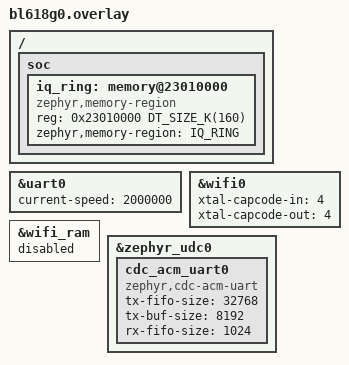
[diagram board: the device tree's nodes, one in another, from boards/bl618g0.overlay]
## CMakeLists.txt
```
# SPDX-FileCopyrightText: Copyright The Zephyr Project Contributors
# SPDX-License-Identifier: Apache-2.0

cmake_minimum_required(VERSION 3.28.0)
find_package(Zephyr REQUIRED HINTS $ENV{ZEPHYR_BASE})
project(bl61x_sdr)

target_sources(app PRIVATE
  src/capture.c
  src/dump_ring.c
  src/iq_control.c
  src/iq_format.c
  src/iq_usb.c
  src/main.c
  src/resample.c
  src/rf.c
  src/stream_ring.c
)
```

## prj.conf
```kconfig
# SPDX-FileCopyrightText: Copyright The Zephyr Project Contributors
# SPDX-License-Identifier: Apache-2.0

CONFIG_BFLB_BL61X_SDR=y
CONFIG_CRC=y
CONFIG_SERIAL=y
CONFIG_UART_INTERRUPT_DRIVEN=y
CONFIG_LOG=n
CONFIG_BOOT_BANNER=n

# USB: vendor stream interface plus CDC-ACM (burst protocol for Web Serial).
# Seven endpoints need the four data FIFOs shared by both directions.
CONFIG_USB_DEVICE_STACK_NEXT=y
CONFIG_UDC_BFLB_V2_FIFO_BIDIR=y
CONFIG_USBD_CDC_ACM_CLASS=y
CONFIG_USBD_CDC_ACM_WORKQUEUE=y
CONFIG_JSON_LIBRARY=y

# UART protocol below the USB stream and producer threads
CONFIG_MAIN_THREAD_PRIORITY=5
CONFIG_MAIN_STACK_SIZE=2048
```

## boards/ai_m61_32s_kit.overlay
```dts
/*
 * SPDX-FileCopyrightText: Copyright The Zephyr Project Contributors
 *
 * SPDX-License-Identifier: Apache-2.0
 */

/* The ESP-SDR web viewer opens the port at 2 MBaud */
&uart0 {
	current-speed = <2000000>;
};

/*
 * RF dump window: all 160 KiB of WRAM, the continuous ring uses the first
 * 128 KiB. The dump engine addresses it as its WRAM bank (0x21010000); the
 * CPU reaches it through the bus remap views at 0x23010000 (non-cached) and
 * 0x63010000 (cached); the 0x21xxxxxx view is not CPU accessible. The
 * wifi_ram region covers the same memory.
 */
&wifi_ram {
	status = "disabled";
};

/ {
	soc {
		iq_ring: memory@23010000 {
			compatible = "zephyr,memory-region", "mmio-sram";
			reg = <0x23010000 DT_SIZE_K(160)>;
			zephyr,memory-region = "IQ_RING";
		};
	};
};

/* Burst protocol over USB CDC-ACM (Web Serial), next to the vendor stream */
&zephyr_udc0 {
	cdc_acm_uart0: cdc_acm_uart0 {
		compatible = "zephyr,cdc-acm-uart";
		tx-fifo-size = <32768>;
		tx-buf-size = <8192>;
		rx-fifo-size = <1024>;
	};
};
```

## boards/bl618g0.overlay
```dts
/*
 * SPDX-FileCopyrightText: Copyright The Zephyr Project Contributors
 *
 * SPDX-License-Identifier: Apache-2.0
 */

/* The ESP-SDR web viewer opens the port at 2 MBaud */
&uart0 {
	current-speed = <2000000>;
};

/*
 * Crystal load trim, measured on a BL618G0 board against a CW reference (the
 * eFuse capcode slots are empty): the default 36 receives 39 ppm high, 4
 * within 1 ppm. Other boards may need a few steps more or less (1.4 ppm/step).
 */
&wifi0 {
	xtal-capcode-in = <4>;
	xtal-capcode-out = <4>;
};

/*
 * RF dump window: all 160 KiB of WRAM, the continuous ring uses the first
 * 128 KiB. The dump engine addresses it as its WRAM bank (0x21010000); the
 * CPU reaches it through the bus remap views at 0x23010000 (non-cached) and
 * 0x63010000 (cached); the 0x21xxxxxx view is not CPU accessible. The
 * wifi_ram region covers the same memory.
 */
&wifi_ram {
	status = "disabled";
};

/ {
	soc {
		iq_ring: memory@23010000 {
			compatible = "zephyr,memory-region", "mmio-sram";
			reg = <0x23010000 DT_SIZE_K(160)>;
			zephyr,memory-region = "IQ_RING";
		};
	};
};

/* Burst protocol over USB CDC-ACM (Web Serial), next to the vendor stream */
&zephyr_udc0 {
	cdc_acm_uart0: cdc_acm_uart0 {
		compatible = "zephyr,cdc-acm-uart";
		tx-fifo-size = <32768>;
		tx-buf-size = <8192>;
		rx-fifo-size = <1024>;
	};
};
```

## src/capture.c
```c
/*
 * SPDX-FileCopyrightText: Copyright The Zephyr Project Contributors
 *
 * SPDX-License-Identifier: Apache-2.0
 */

#include <string.h>

#include <zephyr/kernel.h>
#include <zephyr/spinlock.h>

#include "capture.h"
#include "dump_ring.h"
#include "iq_usb.h"
#include "rf.h"
#include "stream_ring.h"

#define HZ_PER_MHZ                1000000U
#define RF_FREQ_DEFAULT_HZ        (RF_FREQ_DEFAULT_MHZ * HZ_PER_MHZ)
#define RF_FREQ_MIN_HZ            (RF_FREQ_MIN_MHZ * HZ_PER_MHZ)
#define RF_FREQ_MAX_HZ            (RF_FREQ_MAX_MHZ * HZ_PER_MHZ)
#define TX_GAIN_DEFAULT           8U
#define BW_DEFAULT_MHZ            20U
#define LOOPBACK_TX_GAIN_DEFAULT  124U
#define LOOPBACK_RX_GAIN_DEFAULT  0x73U
#define LOOPBACK_BB_GAIN_DEFAULT  0x3fU
#define TX_TONE0_STEP_DEFAULT     16
#define TRIGGER_INTERVAL_DEFAULT  2501U
#define TRIGGER_DURATION_DEFAULT  1U
#define RX_FILTER_BW_OPEN         0U
#define RX_FILTER_BW_MIN_MHZ      13U
#define RX_FILTER_BW_MAX_MHZ      54U
#define RX_FILTER_MODE_DEFAULT    16U
#define RX_FILTER_MODE_MAX        32U
#define RX_FILTER_DCAP_MAX        63U
#define RX_FILTER_NARROW_DCAP     60U
#define WIFI_DUMMY_TX_INTERVAL_MS 1000U
#define IQ_AGC_TRIGGER_STATE_MASK_ALL 0xffffU
#define IQ_AGC_TRIGGER_MATCH_FSM      0U
#define IQ_AGC_TRIGGER_MATCH_MAX_GAIN 1U
#define TRIGGER_CFG_INTERVAL      0U
#define TRIGGER_CFG_OFFSET        1U
#define TRIGGER_CFG_DURATION      2U
#define TRIGGER_CFG_CHECKS        0U
#define TRIGGER_CFG_PRE           1U
#define TRIGGER_CFG_POST          2U
#define TRIGGER_CFG_LEVEL         3U
#define TRIGGER_CFG_STATE_MASK    4U
#define TRIGGER_CFG_DC_SHIFT      4U
#define TRIGGER_CFG_MATCH         5U
#define STALE_APPLY_US            500000U
#define PIPELINE_IDLE_TRIES       100U
#define PIPELINE_IDLE_SLEEP_MS    1
#define ARM_DELAY_MS              100

enum {
	CONFIG_STAGE_APPLY_START = 1U,
	CONFIG_STAGE_AFTER_WIFI = 2U,
	CONFIG_STAGE_BEFORE_MODEM_APPLY = 3U,
	CONFIG_STAGE_AFTER_MODEM_APPLY = 4U,
	CONFIG_STAGE_BEFORE_RESTART = 6U,
	CONFIG_STAGE_AFTER_RESTART = 7U,
	CONFIG_STAGE_RESTART_ENTRY = 20U,
	CONFIG_STAGE_AFTER_ENGINE_ENABLE = 21U,
	CONFIG_STAGE_AFTER_STREAM_STATE = 25U,
};

static struct capture_config config = {
	.radio = {.rf_freq_hz = RF_FREQ_DEFAULT_HZ},
	.gain = {.gain_mode = GAIN_MODE_MANUAL,
		 .rx_gain = RF_GAIN_DEFAULT,
		 .tx_gain = TX_GAIN_DEFAULT},
	.bandwidth = {.bw_mhz = BW_DEFAULT_MHZ, .second_chan = SECOND_CHAN_NONE},
	.loopback = {.loopback_tx_gain = LOOPBACK_TX_GAIN_DEFAULT,
		     .loopback_rx_gain = LOOPBACK_RX_GAIN_DEFAULT,
		     .loopback_bb_gain = LOOPBACK_BB_GAIN_DEFAULT},
	.tx = {.tx_tone0_step = TX_TONE0_STEP_DEFAULT},
	.iq_engine = {.adc_decimation = 1U, .adc_source_sel = 0U},
	.trigger = {.trigger_mode = IQ_TRIGGER_MODE_INTERVAL,
		    .trigger_config = {TRIGGER_INTERVAL_DEFAULT, 0U, TRIGGER_DURATION_DEFAULT}},
	.rx_filter = {.filter_bw_mhz = RX_FILTER_BW_OPEN,
		      .rx_filter_mode = RX_FILTER_MODE_DEFAULT,
		      .rx_filter_dcap = RX_FILTER_NARROW_DCAP},
	.wifi_tx = {.wifi_dummy_tx_interval_ms = WIFI_DUMMY_TX_INTERVAL_MS},
	.dc_offset = {.automatic = 0U},
};
static struct trigger_plan plan;
static struct capture_config pending_config;
static struct trigger_plan pending_plan;
static bool apply_pending;
static bool apply_in_progress;
static uint64_t apply_started_us;
static atomic_t capture_armed;
/* A UART snapshot owns the dump window and the RF tuning */
static bool uart_owner;
static struct k_spinlock lock;

static void arm_work_handler(struct k_work *work);
static K_WORK_DELAYABLE_DEFINE(arm_work, arm_work_handler);

static uint64_t now_us(void);
static struct capture_config sanitize(struct capture_config c);
static struct trigger_plan build_trigger_plan(const struct capture_config *c);
static bool consume_pending(void);
static void finish_apply(void);
static void recover_stale_apply(void);
static void push_stage_report(const struct capture_config *c, uint32_t stage);
static void wait_pipeline_idle(void);
static void engine_disable(void);
static void restart_capture(const struct capture_config *c);
static void apply_pending_config(void);

static uint64_t now_us(void)
{
	return k_cyc_to_us_floor64(k_cycle_get_64());
}

static void arm_work_handler(struct k_work *work)
{
	ARG_UNUSED(work);
	iq_usb_stream_armed_set(true);
}

static struct capture_config sanitize(struct capture_config c)
{
	c.radio.rf_freq_hz = CLAMP(c.radio.rf_freq_hz, RF_FREQ_MIN_HZ, RF_FREQ_MAX_HZ);
	/* rfc_config_channel() resolution is 1 MHz */
	c.radio.rf_freq_hz = ((c.radio.rf_freq_hz + (HZ_PER_MHZ / 2U)) / HZ_PER_MHZ) * HZ_PER_MHZ;
	c.bandwidth.bw_mhz = BW_DEFAULT_MHZ;
	c.bandwidth.second_chan = SECOND_CHAN_NONE;
	c.gain.tx_gain = MIN(c.gain.tx_gain, TX_GAIN_MAX);
	c.dc_offset.automatic = (c.dc_offset.automatic != 0U) ? 1U : 0U;
	if ((c.rx_filter.rx_filter_override == 0U) &&
	    (c.rx_filter.filter_bw_mhz != RX_FILTER_BW_OPEN)) {
		c.rx_filter.filter_bw_mhz = CLAMP(c.rx_filter.filter_bw_mhz, RX_FILTER_BW_MIN_MHZ,
						  RX_FILTER_BW_MAX_MHZ);
	}
	c.rx_filter.rx_filter_dcap = MIN(c.rx_filter.rx_filter_dcap, RX_FILTER_DCAP_MAX);
	c.rx_filter.rx_filter_mode = MIN(c.rx_filter.rx_filter_mode, RX_FILTER_MODE_MAX);

	return c;
}

static struct trigger_plan build_trigger_plan(const struct capture_config *c)
{
	struct trigger_plan p = {
		.mode = c->trigger.trigger_mode,
		.interval_chunks = c->trigger.trigger_config[TRIGGER_CFG_INTERVAL],
		.interval_duration_chunks = c->trigger.trigger_config[TRIGGER_CFG_DURATION],
		.checks_per_chunk = 1U,
	};
	uint32_t sample_stride;

	if (p.interval_chunks == 0U) {
		p.interval_chunks = 1U;
	}
	p.interval_offset_chunks =
		c->trigger.trigger_config[TRIGGER_CFG_OFFSET] % p.interval_chunks;

	if (c->trigger.trigger_mode == IQ_TRIGGER_MODE_AGC) {
		uint32_t match_mode = c->trigger.trigger_config[TRIGGER_CFG_MATCH];

		p.checks_per_chunk = c->trigger.trigger_config[TRIGGER_CFG_CHECKS];
		p.pre_chunks = c->trigger.trigger_config[TRIGGER_CFG_PRE];
		p.post_chunks = c->trigger.trigger_config[TRIGGER_CFG_POST];
		p.max_gain = c->trigger.trigger_config[TRIGGER_CFG_LEVEL];
		p.state_mask = c->trigger.trigger_config[TRIGGER_CFG_STATE_MASK] &
			       IQ_AGC_TRIGGER_STATE_MASK_ALL;
		p.use_fsm_match = match_mode != IQ_AGC_TRIGGER_MATCH_MAX_GAIN;
		p.use_max_gain_match = match_mode != IQ_AGC_TRIGGER_MATCH_FSM;
	} else if (c->trigger.trigger_mode == IQ_TRIGGER_MODE_POWER) {
		p.checks_per_chunk = c->trigger.trigger_config[TRIGGER_CFG_CHECKS];
		p.pre_chunks = c->trigger.trigger_config[TRIGGER_CFG_PRE];
		p.post_chunks = c->trigger.trigger_config[TRIGGER_CFG_POST];
		p.threshold = c->trigger.trigger_config[TRIGGER_CFG_LEVEL];
		p.dc_shift = c->trigger.trigger_config[TRIGGER_CFG_DC_SHIFT];
	} else {
		/* interval mode uses only the interval fields */
	}
	p.checks_per_chunk = CLAMP(p.checks_per_chunk, 1U, IQ_AGC_TRIGGER_MAX_CHECKS_PER_CHUNK);
	sample_stride = MAX(IQ_CHUNK_SAMPLE_WORDS / p.checks_per_chunk, 1U);
	for (uint32_t check = 0U; check < p.checks_per_chunk; check++) {
		p.sample_offsets[check] = (uint16_t)(check * sample_stride);
	}

	return p;
}

static bool consume_pending(void)
{
	k_spinlock_key_t key = k_spin_lock(&lock);
	bool pending = apply_pending && !apply_in_progress;

	if (pending) {
		config = pending_config;
		plan = pending_plan;
		apply_pending = false;
		apply_in_progress = true;
		apply_started_us = now_us();
	}
	k_spin_unlock(&lock, key);

	return pending;
}

static void finish_apply(void)
{
	k_spinlock_key_t key = k_spin_lock(&lock);

	apply_in_progress = false;
	apply_started_us = 0U;
	k_spin_unlock(&lock, key);
}

static void recover_stale_apply(void)
{
	k_spinlock_key_t key = k_spin_lock(&lock);

	if (apply_in_progress && (apply_started_us != 0U) &&
	    ((now_us() - apply_started_us) > STALE_APPLY_US)) {
		apply_in_progress = false;
		apply_started_us = 0U;
	}
	k_spin_unlock(&lock, key);
}

static void push_stage_report(const struct capture_config *c, uint32_t stage)
{
	struct config_report report = {
		.magic = {'C', 'F', 'G', '1'},
		.uptime_ms = k_uptime_get_32(),
		.stage = stage,
		.rx_gain = c->gain.rx_gain,
		.loopback = c->loopback.loopback,
		.tx_tone_enable = c->tx.tx_tone_enable,
		.adc_source_sel = c->iq_engine.adc_source_sel,
		.expert_gain_word0 = c->gain.expert_gain_word0,
		.expert_gain_word1 = c->gain.expert_gain_word1,
		.ctrl = rf_dump_ctrl_read(),
		.mode = rf_dump_cfg_read(),
		.hp_tcm_dump_ctrl = 0U,
		.trigger_interval_chunks = c->trigger.trigger_config[TRIGGER_CFG_INTERVAL],
		.trigger_duration_chunks = c->trigger.trigger_config[TRIGGER_CFG_DURATION],
	};

	(void)stream_ring_push_config_report(&report);
}

static void wait_pipeline_idle(void)
{
	for (uint32_t i = 0U; (i < PIPELINE_IDLE_TRIES) &&
			      (iq_usb_stream_write_active() || dump_ring_producer_active());
	     i++) {
		k_msleep(PIPELINE_IDLE_SLEEP_MS);
	}
}

static void engine_disable(void)
{
	rf_ring_stop();
}

static void restart_capture(const struct capture_config *c)
{
	push_stage_report(c, CONFIG_STAGE_RESTART_ENTRY);
	dump_ring_restart_tracking();
	capture_engine_enable();
	push_stage_report(c, CONFIG_STAGE_AFTER_ENGINE_ENABLE);
	wait_pipeline_idle();
	dump_ring_stream_state_reset();
	push_stage_report(c, CONFIG_STAGE_AFTER_STREAM_STATE);
}

static void apply_pending_config(void)
{
	static struct capture_config applied;
	static bool have_applied;
	struct capture_config c;
	struct trigger_plan p;

	capture_snapshot(&c, &p);
	if (have_applied && (memcmp(&applied, &c, sizeof(c)) == 0) && capture_engine_running()) {
		return;
	}

	push_stage_report(&c, CONFIG_STAGE_APPLY_START);
	wait_pipeline_idle();
	/* Retuning touches the RF block the dump engine reads from */
	engine_disable();
	push_stage_report(&c, CONFIG_STAGE_AFTER_WIFI);
	push_stage_report(&c, CONFIG_STAGE_BEFORE_MODEM_APPLY);
	if (c.gain.gain_mode != GAIN_MODE_AUTO) {
		rf_gain_set(c.gain.rx_gain);
	}
	rf_tune(c.radio.rf_freq_hz / HZ_PER_MHZ);
	rf_dump_sel_set(c.iq_engine.adc_source_sel);
	push_stage_report(&c, CONFIG_STAGE_AFTER_MODEM_APPLY);
	push_stage_report(&c, CONFIG_STAGE_BEFORE_RESTART);
	restart_capture(&c);
	push_stage_report(&c, CONFIG_STAGE_AFTER_RESTART);
	applied = c;
	have_applied = true;
}

void capture_get_config(struct capture_config *out)
{
	k_spinlock_key_t key = k_spin_lock(&lock);

	*out = config;
	k_spin_unlock(&lock, key);
}

void capture_snapshot(struct capture_config *out_config, struct trigger_plan *out_plan)
{
	k_spinlock_key_t key = k_spin_lock(&lock);

	*out_config = config;
	*out_plan = plan;
	k_spin_unlock(&lock, key);
}

const char *capture_validate_config(const struct capture_config *c)
{
	if (c->gain.gain_mode > GAIN_MODE_EXPERT) {
		return "gain_mode must be 0 (auto), 1 (manual), or 2 (expert)";
	}
	if ((c->gain.gain_mode == GAIN_MODE_MANUAL) && (c->gain.rx_gain >= GAIN_TABLE_ENTRIES)) {
		return "manual rx_gain exceeds the calibrated gain table";
	}
	if (c->gain.tx_gain > TX_GAIN_MAX) {
		return "tx_gain must be in the range 0..63";
	}
	if ((c->radio.frequency_correction_ppb < -RF_CORRECTION_MAX_PPB) ||
	    (c->radio.frequency_correction_ppb > RF_CORRECTION_MAX_PPB)) {
		return "frequency_correction_ppb must be in the range -100000..100000";
	}
	if (c->dc_offset.automatic > 1U) {
		return "dc_offset automatic must be 0 or 1";
	}
	/* BL61x dump words carry no AGC state */
	if (c->trigger.trigger_mode == IQ_TRIGGER_MODE_AGC) {
		return "AGC trigger is not supported on BL61x";
	}
	if (c->trigger.trigger_mode > IQ_TRIGGER_MODE_POWER) {
		return "trigger_mode must be 0 (interval), 1 (agc), or 2 (power)";
	}

	return NULL;
}

void capture_apply_config(const struct capture_config *c)
{
	struct capture_config sanitized = sanitize(*c);
	struct trigger_plan p = build_trigger_plan(&sanitized);
	k_spinlock_key_t key = k_spin_lock(&lock);

	pending_config = sanitized;
	pending_plan = p;
	apply_pending = true;
	k_spin_unlock(&lock, key);
}

void capture_service_pending_config(void)
{
	k_spinlock_key_t key = k_spin_lock(&lock);
	bool uart_busy = uart_owner;

	k_spin_unlock(&lock, key);
	/* Deferred until the UART snapshot releases the dump window */
	if (uart_busy) {
		return;
	}

	recover_stale_apply();
	if (consume_pending()) {
		apply_pending_config();
		finish_apply();
	}
	if ((atomic_get(&capture_armed) == 0) && capture_engine_running()) {
		wait_pipeline_idle();
		engine_disable();
		dump_ring_stream_state_reset();
	}
}

bool capture_config_applying(void)
{
	k_spinlock_key_t key = k_spin_lock(&lock);
	bool applying = apply_pending || apply_in_progress;

	k_spin_unlock(&lock, key);

	return applying;
}

/*
 * Stream ownership: a fresh engine start is serialized in the stream thread
 * and the stream is armed only after it and its reports have completed.
 */
void capture_set_armed(bool armed)
{
	k_spinlock_key_t key = k_spin_lock(&lock);

	atomic_set(&capture_armed, armed ? 1 : 0);
	k_spin_unlock(&lock, key);
	if (armed) {
		struct capture_config c;

		/* Keep a configuration the host queued just before arming */
		key = k_spin_lock(&lock);
		c = apply_pending ? pending_config : config;
		k_spin_unlock(&lock, key);
		capture_apply_config(&c);
		(void)k_work_reschedule(&arm_work, K_MSEC(ARM_DELAY_MS));
	} else {
		(void)k_work_cancel_delayable(&arm_work);
		iq_usb_stream_armed_set(false);
	}
}

bool capture_uart_claim(void)
{
	k_spinlock_key_t key = k_spin_lock(&lock);
	bool claimed = (atomic_get(&capture_armed) == 0) && !uart_owner &&
		       !apply_pending && !apply_in_progress && !capture_engine_running();

	if (claimed) {
		uart_owner = true;
	}
	k_spin_unlock(&lock, key);

	return claimed;
}

void capture_uart_release(void)
{
	k_spinlock_key_t key = k_spin_lock(&lock);

	uart_owner = false;
	k_spin_unlock(&lock, key);
}

bool capture_engine_running(void)
{
	return rf_ring_running();
}

void capture_engine_enable(void)
{
	rf_ring_start();
}

uint32_t capture_decimation(const struct capture_config *c)
{
	return CLAMP(c->iq_engine.adc_decimation, 1U, ADC_DECIMATION_MAX);
}

uint32_t capture_sample_rate_hz(const struct capture_config *c)
{
	return RF_SAMPLE_RATE_HZ / capture_decimation(c);
}
```

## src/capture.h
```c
/*
 * SPDX-FileCopyrightText: Copyright The Zephyr Project Contributors
 *
 * SPDX-License-Identifier: Apache-2.0
 */

/*
 * Capture configuration and engine control, mirroring the ESP-SDR streaming
 * firmware: the host configuration document, the trigger plan and the
 * serialized configuration apply sequence.
 */

#ifndef BL61X_SDR_CAPTURE_H_
#define BL61X_SDR_CAPTURE_H_

#include <stdbool.h>
#include <stdint.h>

#include <zephyr/toolchain.h>

#include "rf.h"

#define IQ_TRIGGER_CONFIG_WORDS             16U
#define IQ_AGC_TRIGGER_MAX_CHECKS_PER_CHUNK 32U
#define ADC_DECIMATION_MAX                  10U
#define TX_GAIN_MAX                         63U
#define RF_CORRECTION_MAX_PPB               100000
/* Entries of the RX gain ladder (rf.h) */
#define GAIN_TABLE_ENTRIES                  RF_GAIN_STEPS

enum {
	GAIN_MODE_AUTO = 0U,
	GAIN_MODE_MANUAL = 1U,
	GAIN_MODE_EXPERT = 2U,
};

enum {
	IQ_TRIGGER_MODE_INTERVAL = 0U,
	IQ_TRIGGER_MODE_AGC = 1U,
	IQ_TRIGGER_MODE_POWER = 2U,
};

enum {
	SECOND_CHAN_NONE = 0U,
	SECOND_CHAN_ABOVE = 1U,
	SECOND_CHAN_BELOW = 2U,
};

struct capture_config {
	struct {
		uint32_t stream_wifi_packets;
	} stream;
	struct {
		uint32_t rf_freq_hz;
		int32_t frequency_correction_ppb;
	} radio;
	struct {
		uint32_t gain_mode;
		uint32_t rx_gain;
		uint32_t tx_gain;
		uint32_t expert_gain_word0;
		uint32_t expert_gain_word1;
		uint32_t expert_gain_word2;
	} gain;
	struct {
		uint32_t bw_mhz;
		uint32_t second_chan;
	} bandwidth;
	struct {
		uint32_t loopback;
		uint32_t loopback_tx_gain;
		uint32_t loopback_rx_gain;
		uint32_t loopback_bb_gain;
	} loopback;
	struct {
		uint32_t tx_tone_enable;
		int32_t tx_tone0_step;
	} tx;
	struct {
		uint32_t adc_decimation;
		uint32_t adc_source_sel;
	} iq_engine;
	struct {
		uint32_t trigger_mode;
		uint32_t trigger_config[IQ_TRIGGER_CONFIG_WORDS];
	} trigger;
	struct {
		uint32_t filter_bw_mhz;
		uint32_t rx_filter_override;
		uint32_t rx_filter_mode;
		uint32_t rx_filter_dcap;
	} rx_filter;
	struct {
		uint32_t wifi_dummy_tx_enable;
		uint32_t wifi_dummy_tx_interval_ms;
	} wifi_tx;
	struct {
		uint32_t automatic;
	} dc_offset;
};

BUILD_ASSERT(sizeof(struct capture_config) == 172U, "host CaptureConfig must match firmware");

struct trigger_plan {
	uint32_t mode;
	uint32_t interval_chunks;
	uint32_t interval_offset_chunks;
	uint32_t interval_duration_chunks;
	uint32_t checks_per_chunk;
	uint32_t pre_chunks;
	uint32_t post_chunks;
	uint32_t max_gain;
	uint32_t state_mask;
	uint32_t threshold;
	uint32_t dc_shift;
	bool use_fsm_match;
	bool use_max_gain_match;
	uint16_t sample_offsets[IQ_AGC_TRIGGER_MAX_CHECKS_PER_CHUNK];
};

void capture_get_config(struct capture_config *config);
void capture_snapshot(struct capture_config *config, struct trigger_plan *plan);
/* Validates a host configuration; returns NULL or an error message */
const char *capture_validate_config(const struct capture_config *config);
/* Queues a configuration for the serialized apply in the stream thread */
void capture_apply_config(const struct capture_config *config);
void capture_service_pending_config(void);
bool capture_config_applying(void);
void capture_set_armed(bool armed);
/*
 * Claims the dump window and the RF tuning for a UART command. Fails while a
 * USB host owns the stream or a configuration apply is pending.
 */
bool capture_uart_claim(void);
void capture_uart_release(void);
bool capture_engine_running(void);
void capture_engine_enable(void);
uint32_t capture_decimation(const struct capture_config *config);
uint32_t capture_sample_rate_hz(const struct capture_config *config);

#endif /* BL61X_SDR_CAPTURE_H_ */
```

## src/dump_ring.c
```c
/*
 * SPDX-FileCopyrightText: Copyright The Zephyr Project Contributors
 *
 * SPDX-License-Identifier: Apache-2.0
 */

/*
 * Dump ring consumer, ported from the ESP-SDR streaming firmware.
 *
 * The dump engine writes continuously into a ring of RF_RING_WORDS words.
 * The producer turns the hardware write position into an absolute 64-bit
 * write count, emits fixed chunks that are at least a guard distance behind
 * the writer, skips half a ring and counts drops when it falls too far
 * behind, and queues the chunks as stream frames.
 *
 * Single core adaptation: waits longer than two kernel ticks sleep instead of
 * spinning (ending two ticks early, since a sleep may overshoot), and the
 * producer blocks on the frame queue when it is full, so the transport
 * thread keeps running.
 */

#include <zephyr/kernel.h>
#include <zephyr/sys/util.h>

#include "capture.h"
#include "dump_ring.h"
#include "iq_format.h"
#include "iq_usb.h"
#include "rf.h"
#include "stream_ring.h"

#define RING_GUARD_WORDS          (12U * IQ_CHUNK_SAMPLE_WORDS)
#define LIVE_COPY_GUARD_WORDS     256U
#define RING_MAX_CHUNKS_PER_POLL  16U
#define POLL_CLOSE_US             20U
#define POLL_WAKE_MARGIN_US       30000U
#define POLL_WAKE_SLACK_US        1000U
#define US_PER_MS                 1000U
#define US_PER_S                  1000000ULL
#define TICK_US                   (USEC_PER_SEC / CONFIG_SYS_CLOCK_TICKS_PER_SEC)
/* k_usleep() may overshoot by up to two ticks */
#define SLEEP_SLACK_US            (2U * TICK_US)
#define IDLE_DELAY_MS             2
#define APPLY_DELAY_MS            1
#define SLOT_WAIT_MS              1U
#define DC_Q16_SHIFT              16U
#define DC_Q16_SCALE              65536
#define CHUNKS_PER_WINDOW         (RF_RING_WORDS / IQ_CHUNK_SAMPLE_WORDS)
/* Software AGC in auto gain mode: one chunk measured every interval */
#define AGC_INTERVAL_US           2000U

#define PRODUCER_STACK_SIZE       2048
#define PRODUCER_PRIORITY         3

BUILD_ASSERT((RF_RING_WORDS % IQ_CHUNK_SAMPLE_WORDS) == 0U, "dump ring must be chunk-aligned");

enum {
	CHUNK_STREAM_SKIP = 0U,
	CHUNK_STREAM_TRIGGER = 1U,
	CHUNK_STREAM_PRE = 2U,
	CHUNK_STREAM_POST = 3U,
};

static uint32_t emit_chunk;
static bool ring_started;
static uint32_t source_chunk_index;
static uint32_t dropped_chunks;
static uint64_t abs_write_accum;
static uint32_t prev_sa;
static uint64_t abs_track_us;
static uint32_t dbg_lo;
static uint64_t diag_abs_write;
static uint32_t copy_source_chunk;
static bool power_dc_valid;
static int32_t power_dc_i_q16;
static int32_t power_dc_q_q16;
static volatile bool producer_active;
static uint8_t chunk_mark[RING_MAX_CHUNKS_PER_POLL];
static uint32_t decim_buf[IQ_CHUNK_SAMPLE_WORDS];
static uint64_t agc_last_us;
static uint32_t agc_gain_changes;

static void producer_thread(void *p1, void *p2, void *p3);
K_THREAD_DEFINE(producer_tid, PRODUCER_STACK_SIZE, producer_thread, NULL, NULL, NULL,
		PRODUCER_PRIORITY, 0, SYS_FOREVER_MS);

static uint64_t now_us(void);
static uint32_t ring_mod(uint32_t value);
static uint32_t ring_delta(uint32_t cur, uint32_t prev);
static uint32_t abs_u32(int32_t value);
static uint32_t output_chunk_words(const struct capture_config *config);
static uint32_t ring_guard_words(const struct trigger_plan *plan);
static uint32_t interval_next_selected(const struct trigger_plan *plan, uint32_t chunk);
static uint32_t interval_selected_count(const struct trigger_plan *plan, uint32_t first_chunk,
					uint32_t end_chunk);
static bool interval_prev_selected(const struct trigger_plan *plan, uint32_t end_chunk,
				   uint32_t *selected_chunk);
static bool chunk_triggers(const struct trigger_plan *plan, const uint32_t *words, int32_t *sum_i,
			   int32_t *sum_q, uint32_t *sum_n, int32_t dc_i, int32_t dc_q,
			   bool dc_valid);
static void expand_pre_post(uint8_t *mask, uint32_t n, uint32_t pre, uint32_t post);
static uint64_t current_abs_write(void);
static const uint32_t *chunk_words(const struct capture_config *config, uint32_t start_word);
static const uint32_t *chunk_source(const struct capture_config *config, uint32_t c,
				    uint64_t abs_write);
static const uint32_t *exact_chunk_source(const struct capture_config *config,
					  uint32_t source_chunk);
static void fill_and_push_chunk(const struct capture_config *config, const uint32_t *words,
				uint32_t source_chunk, uint32_t sample_rate_hz, uint32_t rx_gain,
				uint32_t agc_state, union stream_frame *slot);
static void process_interval_exact(const struct capture_config *config,
				   const struct trigger_plan *plan, uint64_t abs_write,
				   uint32_t c_hi, uint32_t sample_rate_hz, uint32_t rx_gain);
static void process_interval_latest(const struct capture_config *config,
				    const struct trigger_plan *plan, uint64_t abs_write,
				    uint32_t c_hi, uint32_t sample_rate_hz, uint32_t rx_gain);
static void process_triggered(const struct capture_config *config,
			      const struct trigger_plan *plan, uint64_t abs_write, uint32_t c_hi,
			      uint32_t sample_rate_hz, uint32_t rx_gain);
static void process_dump_ring(const struct capture_config *config,
			      const struct trigger_plan *plan);
static void agc_service(const struct capture_config *config);
static void wait_until_next_ring_window(const struct capture_config *config,
					const struct trigger_plan *plan);

static uint64_t now_us(void)
{
	return k_cyc_to_us_floor64(k_cycle_get_64());
}

static uint32_t ring_mod(uint32_t value)
{
	return value % RF_RING_WORDS;
}

static uint32_t ring_delta(uint32_t cur, uint32_t prev)
{
	return (cur + RF_RING_WORDS - prev) % RF_RING_WORDS;
}

static uint32_t abs_u32(int32_t value)
{
	return (value < 0) ? (0U - (uint32_t)value) : (uint32_t)value;
}

static uint32_t output_chunk_words(const struct capture_config *config)
{
	return IQ_CHUNK_SAMPLE_WORDS * capture_decimation(config);
}

static uint32_t ring_guard_words(const struct trigger_plan *plan)
{
	if ((plan->mode == IQ_TRIGGER_MODE_INTERVAL) && (plan->interval_chunks == 1U) &&
	    (plan->interval_duration_chunks != 0U)) {
		return LIVE_COPY_GUARD_WORDS;
	}

	return RING_GUARD_WORDS;
}

static uint32_t interval_next_selected(const struct trigger_plan *plan, uint32_t chunk)
{
	uint32_t position;

	if ((plan->interval_chunks == 0U) || (plan->interval_duration_chunks == 0U)) {
		return chunk;
	}
	if (chunk < plan->interval_offset_chunks) {
		return plan->interval_offset_chunks;
	}

	position = (chunk - plan->interval_offset_chunks) % plan->interval_chunks;
	if (position < plan->interval_duration_chunks) {
		return chunk;
	}

	return chunk + (plan->interval_chunks - position);
}

static uint32_t interval_selected_count(const struct trigger_plan *plan, uint32_t first_chunk,
					uint32_t end_chunk)
{
	uint32_t duration;
	uint64_t before_first = 0U;
	uint64_t before_end = 0U;
	uint64_t count;

	if (end_chunk <= first_chunk) {
		return 0U;
	}
	if ((plan->interval_chunks == 0U) || (plan->interval_duration_chunks == 0U)) {
		return end_chunk - first_chunk;
	}

	duration = MIN(plan->interval_duration_chunks, plan->interval_chunks);
	if (first_chunk > plan->interval_offset_chunks) {
		uint32_t rel = first_chunk - plan->interval_offset_chunks;

		before_first = (uint64_t)(rel / plan->interval_chunks) * duration;
		before_first += MIN(rel % plan->interval_chunks, duration);
	}
	if (end_chunk > plan->interval_offset_chunks) {
		uint32_t rel = end_chunk - plan->interval_offset_chunks;

		before_end = (uint64_t)(rel / plan->interval_chunks) * duration;
		before_end += MIN(rel % plan->interval_chunks, duration);
	}
	count = before_end - before_first;

	return (count > UINT32_MAX) ? UINT32_MAX : (uint32_t)count;
}

static bool interval_prev_selected(const struct trigger_plan *plan, uint32_t end_chunk,
				   uint32_t *selected_chunk)
{
	uint32_t duration;
	uint32_t period_index;
	uint32_t period_start;
	uint32_t selected_end;

	if (end_chunk == 0U) {
		return false;
	}
	if ((plan->interval_chunks == 0U) || (plan->interval_duration_chunks == 0U)) {
		*selected_chunk = end_chunk - 1U;
		return true;
	}
	if (end_chunk <= plan->interval_offset_chunks) {
		return false;
	}

	duration = MIN(plan->interval_duration_chunks, plan->interval_chunks);
	period_index = (end_chunk - plan->interval_offset_chunks - 1U) / plan->interval_chunks;
	period_start = plan->interval_offset_chunks + (period_index * plan->interval_chunks);
	selected_end = MIN(period_start + duration, end_chunk);
	if (selected_end > period_start) {
		*selected_chunk = selected_end - 1U;
		return true;
	}
	if (period_index == 0U) {
		return false;
	}
	period_start -= plan->interval_chunks;
	*selected_chunk = period_start + duration - 1U;

	return true;
}

/* Scans one chunk's samples; returns true if it triggers (power mode) */
static bool chunk_triggers(const struct trigger_plan *plan, const uint32_t *words, int32_t *sum_i,
			   int32_t *sum_q, uint32_t *sum_n, int32_t dc_i, int32_t dc_q,
			   bool dc_valid)
{
	bool found = false;

	for (uint32_t check = 0U; check < plan->checks_per_chunk; check++) {
		uint32_t raw = words[plan->sample_offsets[check]];
		int32_t i = iq_format_i10(raw);
		int32_t q = iq_format_q10(raw);
		uint32_t mag = abs_u32(i - dc_i) + abs_u32(q - dc_q);

		*sum_i += i;
		*sum_q += q;
		(*sum_n)++;
		if (dc_valid && (mag >= plan->threshold)) {
			found = true;
		}
	}

	return found;
}

static void expand_pre_post(uint8_t *mask, uint32_t n, uint32_t pre, uint32_t post)
{
	uint32_t last_trig = UINT32_MAX;
	uint32_t next_trig = UINT32_MAX;

	for (uint32_t i = 0U; i < n; i++) {
		if (mask[i] == CHUNK_STREAM_TRIGGER) {
			last_trig = i;
		} else if ((last_trig != UINT32_MAX) && ((i - last_trig) <= post) &&
			   (mask[i] == CHUNK_STREAM_SKIP)) {
			mask[i] = CHUNK_STREAM_POST;
		} else {
			/* outside the post window */
		}
	}
	for (uint32_t j = n; j > 0U; j--) {
		uint32_t i = j - 1U;

		if (mask[i] == CHUNK_STREAM_TRIGGER) {
			next_trig = i;
		} else if ((next_trig != UINT32_MAX) && ((next_trig - i) <= pre) &&
			   (mask[i] == CHUNK_STREAM_SKIP)) {
			mask[i] = CHUNK_STREAM_PRE;
		} else {
			/* outside the pre window */
		}
	}
}

/*
 * Accumulates the writer position. When more than half a ring may have
 * passed since the last poll, the elapsed time resolves the wrap count.
 */
static uint64_t current_abs_write(void)
{
	uint64_t now = now_us();
	uint32_t raw_sa = rf_ring_store_addr_raw();
	uint32_t sa = ring_mod(raw_sa);
	uint32_t delta_mod = ring_delta(sa, prev_sa);
	uint32_t delta = delta_mod;

	if (abs_track_us != 0U) {
		uint64_t expected = ((now - abs_track_us) * RF_SAMPLE_RATE_HZ) / US_PER_S;

		if (expected > (RF_RING_WORDS / 2U)) {
			uint64_t wraps = 0U;
			uint64_t delta64;

			if (expected > delta_mod) {
				wraps = (expected - delta_mod + (RF_RING_WORDS / 2U)) /
					RF_RING_WORDS;
			}
			delta64 = (uint64_t)delta_mod + (wraps * RF_RING_WORDS);
			delta = (delta64 > UINT32_MAX) ? UINT32_MAX : (uint32_t)delta64;
		}
	}

	abs_write_accum += delta;
	prev_sa = sa;
	abs_track_us = now;
	dbg_lo = raw_sa;
	diag_abs_write = abs_write_accum;

	return abs_write_accum;
}

static const uint32_t *chunk_words(const struct capture_config *config, uint32_t start_word)
{
	volatile uint32_t *ring = rf_ring_base();
	uint32_t decimation = capture_decimation(config);
	uint32_t source = ring_mod(start_word);

	/* The ring view is non-cached: no maintenance before reading */
	if (decimation == 1U) {
		return (const uint32_t *)&ring[source];
	}

	for (uint32_t i = 0U; i < IQ_CHUNK_SAMPLE_WORDS; i++) {
		decim_buf[i] = ring[source];
		source += decimation;
		if (source >= RF_RING_WORDS) {
			source -= RF_RING_WORDS;
		}
	}

	return decim_buf;
}

static const uint32_t *chunk_source(const struct capture_config *config, uint32_t c,
				    uint64_t abs_write)
{
	uint32_t output_words = output_chunk_words(config);
	uint64_t start_abs = (uint64_t)c * output_words;
	uint32_t start_word = (uint32_t)(start_abs % RF_RING_WORDS);
	uint32_t physical_chunk = (start_word / IQ_CHUNK_SAMPLE_WORDS) % CHUNKS_PER_WINDOW;
	uint64_t abs_chunk = abs_write / output_words;
	int32_t physical_delta =
		(int32_t)physical_chunk - (int32_t)(uint32_t)(abs_chunk % CHUNKS_PER_WINDOW);
	int64_t source_abs;

	if (physical_delta > 0) {
		physical_delta -= (int32_t)CHUNKS_PER_WINDOW;
	}
	source_abs = (int64_t)abs_chunk + physical_delta;
	copy_source_chunk = (source_abs > 0) ? (uint32_t)source_abs : 0U;

	return chunk_words(config, start_word);
}

static const uint32_t *exact_chunk_source(const struct capture_config *config,
					  uint32_t source_chunk)
{
	uint64_t start_abs = (uint64_t)source_chunk * output_chunk_words(config);

	copy_source_chunk = source_chunk;

	return chunk_words(config, (uint32_t)(start_abs % RF_RING_WORDS));
}

static void fill_and_push_chunk(const struct capture_config *config, const uint32_t *words,
				uint32_t source_chunk, uint32_t sample_rate_hz, uint32_t rx_gain,
				uint32_t agc_state, union stream_frame *slot)
{
	struct iq_chunk_report_meta meta = {
		.source_chunk_index = source_chunk,
		.adc_decimation = capture_decimation(config),
		.sample_rate_hz = sample_rate_hz,
		.center_freq_mhz = rf_freq_mhz(),
		.rx_gain = rx_gain,
		.agc_state = agc_state,
		.software_agc_active = config->gain.gain_mode == GAIN_MODE_AUTO,
		.agc_gain_changes = agc_gain_changes,
		.dropped_chunks = dropped_chunks,
		.bank_timer_late_misses = 0U,
		.bank_timer_write_ptr = dbg_lo,
		.producer_wake_write_ptr = rf_ring_store_addr_raw(),
	};

	if (iq_usb_stream_format() == IQ_USB_FORMAT_INT8) {
		stream_ring_fill_iq_chunk_int8(slot, &meta, words);
	} else {
		stream_ring_fill_iq_chunk(slot, &meta, words);
	}
}

/* Gapless interval: every chunk from the oldest one still in the ring */
static void process_interval_exact(const struct capture_config *config,
				   const struct trigger_plan *plan, uint64_t abs_write,
				   uint32_t c_hi, uint32_t sample_rate_hz, uint32_t rx_gain)
{
	uint32_t output_words = output_chunk_words(config);
	uint64_t low_abs = (abs_write > RF_RING_WORDS) ? (abs_write - RF_RING_WORDS + output_words)
						       : 0U;
	uint32_t low_chunk = (uint32_t)((low_abs + output_words - 1U) / output_words);
	union stream_frame *slots[RING_MAX_CHUNKS_PER_POLL];
	uint32_t n;

	ARG_UNUSED(plan);

	if (emit_chunk < low_chunk) {
		dropped_chunks += low_chunk - emit_chunk;
		emit_chunk = low_chunk;
	}
	if (emit_chunk >= c_hi) {
		source_chunk_index = emit_chunk;
		return;
	}

	n = MIN(MIN(c_hi - emit_chunk, RING_MAX_CHUNKS_PER_POLL), stream_ring_available_slots());
	if (n == 0U) {
		source_chunk_index = emit_chunk;
		return;
	}
	if (!stream_ring_reserve_slots(n, slots)) {
		return;
	}
	for (uint32_t i = 0U; i < n; i++) {
		uint32_t source_chunk = emit_chunk + i;

		fill_and_push_chunk(config, exact_chunk_source(config, source_chunk), source_chunk,
				    sample_rate_hz, rx_gain, 0U, slots[i]);
	}
	stream_ring_commit_reserved(n);
	emit_chunk += n;
	source_chunk_index = emit_chunk;
}

/* Sparse interval: only the newest selected chunk, older ones count as drops */
static void process_interval_latest(const struct capture_config *config,
				    const struct trigger_plan *plan, uint64_t abs_write,
				    uint32_t c_hi, uint32_t sample_rate_hz, uint32_t rx_gain)
{
	uint32_t output_words = output_chunk_words(config);
	uint64_t low_abs = (abs_write > RF_RING_WORDS) ? (abs_write - RF_RING_WORDS + output_words)
						       : 0U;
	uint32_t low_chunk = (uint32_t)((low_abs + output_words - 1U) / output_words);
	union stream_frame *slots[1];
	uint32_t latest;

	if (!interval_prev_selected(plan, c_hi, &latest)) {
		return;
	}
	if (latest < low_chunk) {
		dropped_chunks += interval_selected_count(plan, emit_chunk, low_chunk);
		emit_chunk = interval_next_selected(plan, low_chunk);
		source_chunk_index = emit_chunk;
		return;
	}
	if (latest < emit_chunk) {
		source_chunk_index = emit_chunk;
		return;
	}

	dropped_chunks += interval_selected_count(plan, emit_chunk, latest);
	if (!stream_ring_reserve_slots(1U, slots)) {
		dropped_chunks++;
		return;
	}
	fill_and_push_chunk(config, exact_chunk_source(config, latest), latest, sample_rate_hz,
			    rx_gain, 0U, slots[0]);
	stream_ring_commit_reserved(1U);
	emit_chunk = interval_next_selected(plan, latest + 1U);
	source_chunk_index = emit_chunk;
}

/* Power trigger: marks triggering chunks and their pre/post neighbours */
static void process_triggered(const struct capture_config *config,
			      const struct trigger_plan *plan, uint64_t abs_write, uint32_t c_hi,
			      uint32_t sample_rate_hz, uint32_t rx_gain)
{
	union stream_frame *slots[RING_MAX_CHUNKS_PER_POLL];
	uint32_t n = MIN(c_hi - emit_chunk, RING_MAX_CHUNKS_PER_POLL);
	int32_t dc_i = power_dc_i_q16 >> DC_Q16_SHIFT;
	int32_t dc_q = power_dc_q_q16 >> DC_Q16_SHIFT;
	int32_t sum_i = 0;
	int32_t sum_q = 0;
	uint32_t sum_n = 0U;
	uint32_t selected = 0U;
	uint32_t reserve;
	uint32_t filled = 0U;

	for (uint32_t k = 0U; k < n; k++) {
		const uint32_t *words = chunk_source(config, emit_chunk + k, abs_write);

		chunk_mark[k] = chunk_triggers(plan, words, &sum_i, &sum_q, &sum_n, dc_i, dc_q,
					       power_dc_valid)
					? CHUNK_STREAM_TRIGGER
					: CHUNK_STREAM_SKIP;
	}
	expand_pre_post(chunk_mark, n, plan->pre_chunks, plan->post_chunks);
	if (sum_n != 0U) {
		int32_t mean_i = (sum_i / (int32_t)sum_n) * DC_Q16_SCALE;
		int32_t mean_q = (sum_q / (int32_t)sum_n) * DC_Q16_SCALE;

		if (!power_dc_valid) {
			power_dc_i_q16 = mean_i;
			power_dc_q_q16 = mean_q;
			power_dc_valid = true;
		} else {
			power_dc_i_q16 += (mean_i - power_dc_i_q16) >> plan->dc_shift;
			power_dc_q_q16 += (mean_q - power_dc_q_q16) >> plan->dc_shift;
		}
	}

	for (uint32_t k = 0U; k < n; k++) {
		if (chunk_mark[k] != CHUNK_STREAM_SKIP) {
			selected++;
		}
	}
	reserve = MIN(selected, stream_ring_available_slots());
	dropped_chunks += selected - reserve;
	if ((reserve != 0U) && !stream_ring_reserve_slots(reserve, slots)) {
		dropped_chunks += reserve;
		reserve = 0U;
	}
	for (uint32_t k = 0U; (k < n) && (filled < reserve); k++) {
		if (chunk_mark[k] != CHUNK_STREAM_SKIP) {
			const uint32_t *words = chunk_source(config, emit_chunk + k, abs_write);

			fill_and_push_chunk(config, words, copy_source_chunk, sample_rate_hz,
					    rx_gain, 0U, slots[filled]);
			filled++;
		}
	}
	stream_ring_commit_reserved(filled);
	stream_ring_release_reserved(reserve - filled);
	emit_chunk += n;
	source_chunk_index = emit_chunk;
}

static void process_dump_ring(const struct capture_config *config,
			      const struct trigger_plan *plan)
{
	uint64_t abs_write = current_abs_write();
	uint32_t guard_words = ring_guard_words(plan);
	uint32_t output_words = output_chunk_words(config);
	uint32_t sample_rate_hz;
	uint32_t rx_gain;
	uint64_t hi;
	uint64_t emit_abs;
	uint32_t c_hi;

	if (abs_write <= guard_words) {
		return;
	}

	hi = abs_write - guard_words;
	c_hi = (uint32_t)(hi / output_words);
	if (!ring_started) {
		emit_chunk = (c_hi > 0U) ? (c_hi - 1U) : 0U;
		if (plan->mode == IQ_TRIGGER_MODE_INTERVAL) {
			emit_chunk = interval_next_selected(plan, emit_chunk);
		}
		ring_started = true;
	}

	emit_abs = (uint64_t)emit_chunk * output_words;
	if ((hi > emit_abs) && ((hi - emit_abs) > (RF_RING_WORDS - guard_words))) {
		uint32_t new_emit = (uint32_t)((hi - (RF_RING_WORDS / 2U)) / output_words);

		if (plan->mode == IQ_TRIGGER_MODE_INTERVAL) {
			dropped_chunks += interval_selected_count(plan, emit_chunk, new_emit);
			emit_chunk = interval_next_selected(plan, new_emit);
		} else {
			dropped_chunks += new_emit - emit_chunk;
			emit_chunk = new_emit;
		}
	}
	if (c_hi <= emit_chunk) {
		return;
	}

	sample_rate_hz = capture_sample_rate_hz(config);
	rx_gain = rf_gain_get();

	if (plan->mode != IQ_TRIGGER_MODE_INTERVAL) {
		process_triggered(config, plan, abs_write, c_hi, sample_rate_hz, rx_gain);
	} else if ((plan->interval_chunks == 1U) && (plan->interval_duration_chunks != 0U)) {
		process_interval_exact(config, plan, abs_write, c_hi, sample_rate_hz, rx_gain);
	} else {
		process_interval_latest(config, plan, abs_write, c_hi, sample_rate_hz, rx_gain);
	}
}

/* Measures the newest complete chunk behind the writer and adjusts the gain */
static void agc_service(const struct capture_config *config)
{
	uint64_t now = now_us();
	uint32_t start;

	if ((config->gain.gain_mode != GAIN_MODE_AUTO) || ((now - agc_last_us) < AGC_INTERVAL_US) ||
	    (diag_abs_write < (RING_GUARD_WORDS + IQ_CHUNK_SAMPLE_WORDS))) {
		return;
	}
	agc_last_us = now;
	start = ring_mod((uint32_t)(diag_abs_write - RING_GUARD_WORDS - IQ_CHUNK_SAMPLE_WORDS));
	start -= start % IQ_CHUNK_SAMPLE_WORDS;
	if (!rf_agc_update(&rf_ring_base()[start], IQ_CHUNK_SAMPLE_WORDS)) {
		agc_gain_changes++;
	}
}

static void wait_until_next_ring_window(const struct capture_config *config,
					const struct trigger_plan *plan)
{
	uint32_t next_chunk = emit_chunk;
	uint64_t ready_abs;
	uint64_t remaining_words;
	uint32_t remaining_us;

	if (plan->mode == IQ_TRIGGER_MODE_INTERVAL) {
		next_chunk = interval_next_selected(plan, next_chunk);
	}
	ready_abs = (((uint64_t)next_chunk + 1U) * output_chunk_words(config)) +
		    ring_guard_words(plan);
	if (ready_abs <= diag_abs_write) {
		k_yield();
		return;
	}

	remaining_words = ready_abs - diag_abs_write;
	remaining_us = (uint32_t)MIN((remaining_words * US_PER_S) / RF_SAMPLE_RATE_HZ, UINT32_MAX);
	if (remaining_us > (POLL_WAKE_MARGIN_US + POLL_WAKE_SLACK_US)) {
		k_msleep((int32_t)((remaining_us - POLL_WAKE_MARGIN_US) / US_PER_MS));
	} else if (remaining_us > (SLEEP_SLACK_US + POLL_CLOSE_US)) {
		/* Wake early; the next pass busy-waits the remainder */
		k_usleep((int32_t)(remaining_us - SLEEP_SLACK_US));
	} else if (remaining_us > POLL_CLOSE_US) {
		k_busy_wait(remaining_us - POLL_CLOSE_US);
		k_yield();
	} else {
		k_busy_wait(POLL_CLOSE_US);
		k_yield();
	}
}

static void producer_thread(void *p1, void *p2, void *p3)
{
	struct capture_config config;
	struct trigger_plan plan;

	ARG_UNUSED(p1);
	ARG_UNUSED(p2);
	ARG_UNUSED(p3);

	for (;;) {
		/* Set before the checks so wait_pipeline_idle() cannot miss a pass */
		producer_active = true;
		if (!iq_usb_stream_armed()) {
			producer_active = false;
			k_msleep(IDLE_DELAY_MS);
			continue;
		}
		if (capture_config_applying()) {
			producer_active = false;
			k_msleep(APPLY_DELAY_MS);
			continue;
		}
		capture_snapshot(&config, &plan);
		if (!capture_engine_running()) {
			capture_engine_enable();
			dump_ring_stream_state_reset();
			producer_active = false;
			k_msleep(APPLY_DELAY_MS);
			continue;
		}

		process_dump_ring(&config, &plan);
		agc_service(&config);
		producer_active = false;

		if (stream_ring_available_slots() == 0U) {
			(void)stream_ring_wait_slots(SLOT_WAIT_MS);
		} else {
			wait_until_next_ring_window(&config, &plan);
		}
	}
}

void dump_ring_init(void)
{
	k_thread_name_set(producer_tid, "iq_producer");
	k_thread_start(producer_tid);
}

void dump_ring_restart_tracking(void)
{
	prev_sa = 0U;
	abs_write_accum = 0U;
	abs_track_us = 0U;
}

void dump_ring_stream_state_reset(void)
{
	stream_ring_reset();
	dropped_chunks = 0U;
	source_chunk_index = 0U;
	emit_chunk = 0U;
	ring_started = false;
	abs_track_us = 0U;
	power_dc_valid = false;
	power_dc_i_q16 = 0;
	power_dc_q_q16 = 0;
	/* The engine may already be running: keep abs_write % ring equal to the
	 * physical write position so chunk offsets address the right words
	 */
	prev_sa = ring_mod(rf_ring_store_addr_raw());
	abs_write_accum = prev_sa;
	diag_abs_write = prev_sa;
}

bool dump_ring_producer_active(void)
{
	return producer_active;
}

uint32_t dump_ring_dropped_chunks(void)
{
	return dropped_chunks;
}

uint32_t dump_ring_source_chunk_index(void)
{
	return source_chunk_index;
}

uint64_t dump_ring_abs_write(void)
{
	return diag_abs_write;
}

uint32_t dump_ring_agc_gain_changes(void)
{
	return agc_gain_changes;
}
```

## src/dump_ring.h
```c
/*
 * SPDX-FileCopyrightText: Copyright The Zephyr Project Contributors
 *
 * SPDX-License-Identifier: Apache-2.0
 */

#ifndef BL61X_SDR_DUMP_RING_H_
#define BL61X_SDR_DUMP_RING_H_

#include <stdbool.h>
#include <stdint.h>

void dump_ring_init(void);
void dump_ring_restart_tracking(void);
void dump_ring_stream_state_reset(void);
bool dump_ring_producer_active(void);
uint32_t dump_ring_dropped_chunks(void);
uint32_t dump_ring_source_chunk_index(void);
uint32_t dump_ring_agc_gain_changes(void);
/* Latest absolute write position in words */
uint64_t dump_ring_abs_write(void);

#endif /* BL61X_SDR_DUMP_RING_H_ */
```

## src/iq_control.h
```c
/*
 * SPDX-FileCopyrightText: Copyright The Zephyr Project Contributors
 *
 * SPDX-License-Identifier: Apache-2.0
 */

/* JSON documents of the ESP-SDR control API (config and status) */

#ifndef BL61X_SDR_IQ_CONTROL_H_
#define BL61X_SDR_IQ_CONTROL_H_

#include <stddef.h>
#include <stdint.h>

#include "capture.h"

int iq_control_build_config_json(char *text, size_t cap);
int iq_control_build_status_json(char *text, size_t cap);
/*
 * Parses a configuration document on top of the current configuration.
 * Returns NULL on success or an error message.
 */
const char *iq_control_parse_config_json(char *json, size_t len, struct capture_config *config);
/* Reads "stream_format" from a stream-start document */
uint32_t iq_control_parse_stream_format(char *json, size_t len, uint32_t fallback);

#endif /* BL61X_SDR_IQ_CONTROL_H_ */
```

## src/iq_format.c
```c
/*
 * SPDX-FileCopyrightText: Copyright The Zephyr Project Contributors
 *
 * SPDX-License-Identifier: Apache-2.0
 */

#include <zephyr/sys/util.h>

#include "iq_format.h"

/* Default guess for the dump word layout */
/* ESP-SDR orientation, measured with a CW tone: I in bits 31:16, Q in bits 15:0 */
#define I_LSB_DEFAULT  16U
#define Q_LSB_DEFAULT  0U
/* Measured: 11-bit signed samples, sign-extended to 16 bits */
#define WIDTH_DEFAULT  IQ_FORMAT_WIDTH_DEFAULT
#define IQ10_BITS      10U
#define IQ8_SHIFT      2U
#define BYTE_BITS      8U
#define BYTE_MASK      0xffU
#define WORD_BITS      32U

static uint32_t i_lsb = I_LSB_DEFAULT;
static uint32_t q_lsb = Q_LSB_DEFAULT;
static uint32_t width = WIDTH_DEFAULT;

static int32_t field10(uint32_t word, uint32_t lsb);

static int32_t field10(uint32_t word, uint32_t lsb)
{
	uint32_t raw = (word >> lsb) & (BIT(width) - 1U);
	int32_t val = (int32_t)raw;

	if ((raw & BIT(width - 1U)) != 0U) {
		val -= (int32_t)BIT(width);
	}
	if (width > IQ10_BITS) {
		uint32_t shift = width - IQ10_BITS;

		/* Floor, as an arithmetic shift, using shifts of non-negative values */
		uint32_t round = (uint32_t)BIT(shift) - 1U;

		val = (val >= 0) ? (int32_t)((uint32_t)val >> shift)
				 : -(int32_t)(((uint32_t)(-val) + round) >> shift);
	} else {
		val *= (int32_t)BIT(IQ10_BITS - width);
	}

	return val;
}

bool iq_format_is_default(void)
{
	return (i_lsb == I_LSB_DEFAULT) && (q_lsb == Q_LSB_DEFAULT) && (width == WIDTH_DEFAULT);
}

bool iq_format_set(uint32_t new_i_lsb, uint32_t new_q_lsb, uint32_t new_width)
{
	if ((new_width == 0U) || (new_width > IQ_FORMAT_WIDTH_MAX) ||
	    ((new_i_lsb + new_width) > WORD_BITS) || ((new_q_lsb + new_width) > WORD_BITS)) {
		return false;
	}

	i_lsb = new_i_lsb;
	q_lsb = new_q_lsb;
	width = new_width;

	return true;
}

void iq_format_get(uint32_t *out_i_lsb, uint32_t *out_q_lsb, uint32_t *out_width)
{
	*out_i_lsb = i_lsb;
	*out_q_lsb = q_lsb;
	*out_width = width;
}

int32_t iq_format_i10(uint32_t word)
{
	return field10(word, i_lsb);
}

int32_t iq_format_q10(uint32_t word)
{
	return field10(word, q_lsb);
}

/* Top 8 of the 10 bits, as the ESP-SDR packer (floor, not truncation) */
uint16_t iq_format_iq8(uint32_t word)
{
	uint32_t i8 = ((uint32_t)iq_format_i10(word) >> IQ8_SHIFT) & BYTE_MASK;
	uint32_t q8 = ((uint32_t)iq_format_q10(word) >> IQ8_SHIFT) & BYTE_MASK;

	return (uint16_t)(i8 | (q8 << BYTE_BITS));
}
```

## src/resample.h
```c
/*
 * SPDX-FileCopyrightText: Copyright The Zephyr Project Contributors
 *
 * SPDX-License-Identifier: Apache-2.0
 */

/* Rational resampling of dump words by a polyphase FIR */

#ifndef BL61X_SDR_RESAMPLE_H_
#define BL61X_SDR_RESAMPLE_H_

#include <stdint.h>

struct resample {
	/* Lowpass taps (Q15) at the input rate times up, DC gain up */
	const int16_t *taps;
	uint32_t len;
	uint32_t up;
	uint32_t down;
};

/* 40 MS/s to 20 MS/s: passband 8 MHz, 70 dB stopband from 12 MHz */
extern const struct resample resample_40m_20m;
/* 40 MS/s to 16 MS/s: passband 6 MHz, 69 dB stopband from 10 MHz */
extern const struct resample resample_40m_16m;

/* Input words that cover n output samples */
uint32_t resample_input_words(const struct resample *r, uint32_t n);

/*
 * Filters in_words dump words (signed I in bits 15:0, Q in bits 31:16) into
 * n words of the same layout, saturated to width bits. The outputs are
 * centered on the input; taps reaching outside it see zeros.
 */
void resample_run(const struct resample *r, const uint32_t *in, uint32_t in_words, uint32_t *out,
		  uint32_t n, uint32_t width);

#endif /* BL61X_SDR_RESAMPLE_H_ */
```
